# SAM9X60D1G_SOM register map
Vendor: Microchip Technology; Series: SAM9X6; File version: 0
Registers are 32-bit, read-write, reset 0x0 unless marked. A register's access mark holds for its fields unless they carry their own. Offsets are from the block's base; [hi:lo] are bit positions; lines under a group give offsets from that group; {n}, {i} and the like mark numbered series; 'fields as' and 'values as' point back to an identical list.

## PIT — Periodic Interval Timer
Base 0xFFFFFE40
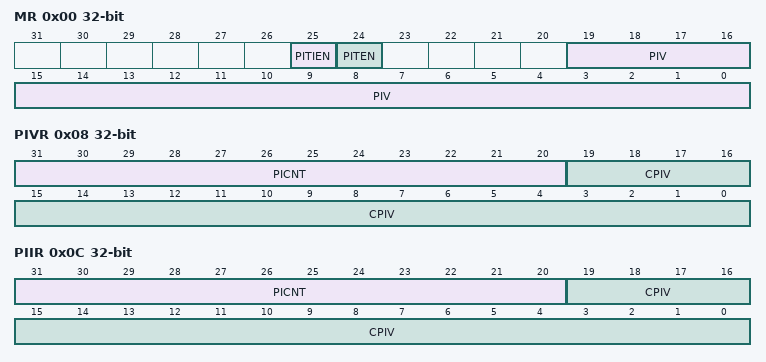
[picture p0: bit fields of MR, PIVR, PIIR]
0x00 MR — Mode Register
  [25] PITIEN — Periodic Interval Timer Interrupt Enable
  [24] PITEN — Period Interval Timer Enabled
  [19:0] PIV — Periodic Interval Value
0x04 SR ro — Status Register
  [0] PITS — Periodic Interval Timer Status
0x08 PIVR ro — Periodic Interval Value Register
  [31:20] PICNT — Periodic Interval Counter
  [19:0] CPIV — Current Periodic Interval Value
0x0C PIIR ro — Periodic Interval Image Register
  fields as PIVR

## PIT64B — Periodic Interval Timer 64-bit
Base 0xF0028000
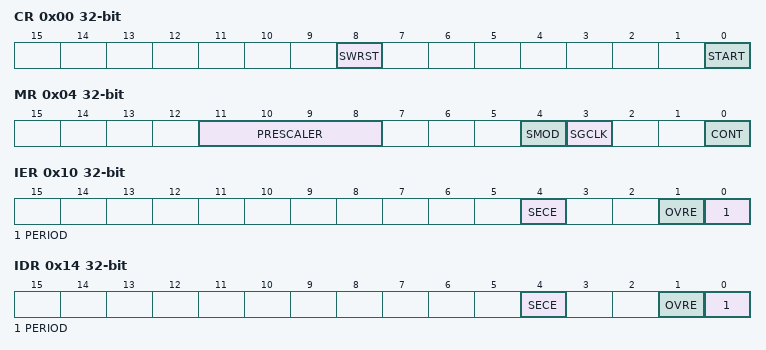
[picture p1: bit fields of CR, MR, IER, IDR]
0x00 CR wo — Control Register
  [8] SWRST — Software Reset
  [0] START — Start Timer
0x04 MR — Mode Register
  [11:8] PRESCALER — Prescaler Period
  [4] SMOD — Start Mode
  [3] SGCLK — Generic Clock Selection Enable
  [0] CONT — Continuous Mode
0x08 LSBPR — LSB Period Register
  [31:0] LSBPERIOD — 32 LSB of the Timer Period
0x0C MSBPR — MSB Period Register
  [31:0] MSBPERIOD — 32 MSB of the Timer Period
0x10 IER wo — Interrupt Enable Register
  [4] SECE — Safety and/or Security Report Interrupt Enable
  [1] OVRE — Overrun Error Interrupt Enable
  [0] PERIOD — Elapsed Timer Period Interrupt Enable
0x14 IDR wo — Interrupt Disable Register
  [4] SECE — Safety and/or Security Report Interrupt Disable
  [1] OVRE — Overrun Error Interrupt Disable
  [0] PERIOD — Elapsed Timer Period Interrupt Disable
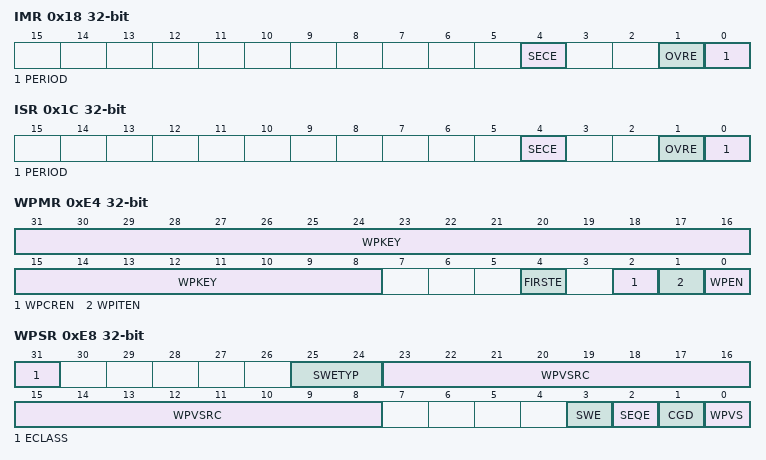
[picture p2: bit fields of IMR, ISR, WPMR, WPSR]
0x18 IMR ro — Interrupt Mask Register
  [4] SECE — Safety and/or Security Report Interrupt Mask
  [1] OVRE — Overrun Error Interrupt Mask
  [0] PERIOD — Elapsed Timer Period Interrupt Mask
0x1C ISR ro — Interrupt Status Register
  [4] SECE — Safety/Security Report (cleared on read)
  [1] OVRE — Overrun Error (cleared on read)
  [0] PERIOD — Elapsed Timer Period Status Flag (cleared on read)
0x20 TLSBR ro — Timer LSB Current Value Register
  [31:0] LSBTIMER — Current 32 LSB of the Timer
0x24 TMSBR ro — Timer MSB Current Value Register
  [31:0] MSBTIMER — Current 32 MSB of the Timer
0xE4 WPMR — Write Protection Mode Register
  [31:8] WPKEY — Write Protection Key
    0x504954=PASSWD (Writing any other value in this field aborts the write operation of the WPCREN, WPITEN and WPEN bits. Always reads as 0.)
  [4] FIRSTE — First Error Report Enable
  [2] WPCREN — Write Protection Control Enable
  [1] WPITEN — Write Protection Interruption Enable
  [0] WPEN — Write Protection Enable
0xE8 WPSR ro — Write Protection Status Register
  [31] ECLASS — Software Error Class (cleared on read)
    0=WARNING (An abnormal access that does not affect system functionality.); 1=ERROR (A write access is performed into PIT64B_MR, PIT64B_LSBR, PIT64B_MSBR while the PIT64B is running.)
  [25:24] SWETYP — Software Error Type (cleared on read)
    0=READ_WO (A write-only register has been read (warning).); 1=WRITE_RO (A write access has been performed on a read-only register (Warning).); 2=UNDEF_RW (Access to an undefined address (warning).); 3=WEIRD_ACTION (A write access is performed into PIT64B_MR, PIT64B_LSBR, PIT64B_MSBR while the PIT64B is running (abnormal).)
  [23:8] WPVSRC — Write Protection Violation Source
  [3] SWE — Software Control Error (cleared on read)
  [2] SEQE — Internal Sequencer Error (cleared on read)
  [1] CGD — Clock Glitch Detected (cleared on read)
  [0] WPVS — Write Protection Violation Status (cleared on read)

## PMECC — Programmable Multibit Error Correction Code Controller
Base 0xFFFFE000
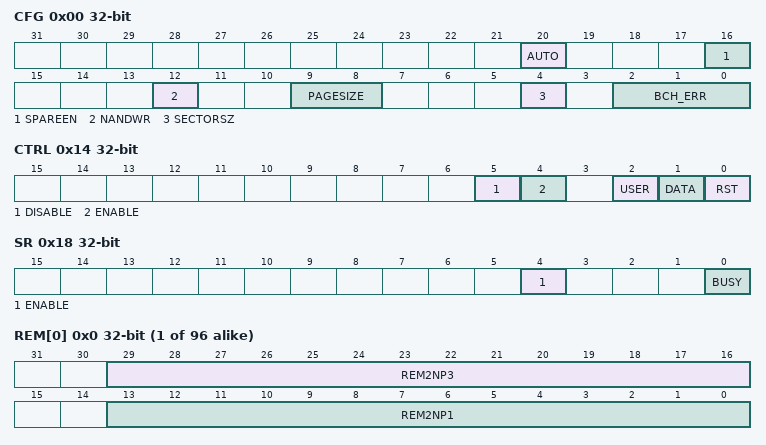
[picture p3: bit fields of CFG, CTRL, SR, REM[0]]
0x00 CFG — PMECC Configuration Register
  [20] AUTO — Automatic Mode Enable
  [16] SPAREEN — Spare Enable
  [12] NANDWR — NAND Write Access
  [9:8] PAGESIZE — Number of Sectors in the Page
    0=PAGESIZE_1SEC (1 sector for main area (512 or 1024 bytes)); 1=PAGESIZE_2SEC (2 sectors for main area (1024 or 2048 bytes)); 2=PAGESIZE_4SEC (4 sectors for main area (2048 or 4096 bytes)); 3=PAGESIZE_8SEC (8 sectors for main area (4096 or 8192 bytes))
  [4] SECTORSZ — Sector Size
  [2:0] BCH_ERR — Error Correct Capability
    0=2 errors; 1=4 errors; 2=8 errors; 3=12 errors; 4=24 errors
0x04 SAREA — PMECC Spare Area Size Register
  [8:0] SPARESIZE — Spare Area Size
0x08 SADDR — PMECC Start Address Register
  [8:0] STARTADDR — ECC Area Start Address (byte oriented address)
0x0C EADDR — PMECC End Address Register
  [8:0] ENDADDR — ECC Area End Address (byte oriented address)
0x10 CLK — PMECC Clock Control Register
  [2:0] CLKCTRL — Clock Control Register
0x14 CTRL wo — PMECC Control Register
  [5] DISABLE — PMECC Module Disable
  [4] ENABLE — PMECC Module Enable
  [2] USER — Start a User Mode Phase
  [1] DATA — Start a Data Phase
  [0] RST — Reset the PMECC Module
0x18 SR ro — PMECC Status Register
  [4] ENABLE — PMECC Module Status
  [0] BUSY — The Kernel of the PMECC is Busy
0x1C IER wo — PMECC Interrupt Enable register
  [0] ERRIE — Error Interrupt Enable
0x20 IDR wo — PMECC Interrupt Disable Register
  [0] ERRID — Error Interrupt Disable
0x24 IMR ro — PMECC Interrupt Mask Register
  [0] ERRIM — Error Interrupt Mask
0x28 ISR ro — PMECC Interrupt Status Register
  [7:0] ERRIS — Error Interrupt Status
{0x40+0x40*i} PMECC_ECC[{i}] (i=0..7) group
  {0x0+4j} ECC[{j}] (j=0..10) ro — PMECC ECC 0 Register (sec_num = 0)
    [31:0] ECC — BCH Redundancy
{0x240+0x40*i} PMECC_REM[{i}] (i=0..7) group
  {0x0+4j} REM[{j}] (j=0..11) ro — PMECC REM 0 Register (sec_num = 0)
    [29:16] REM2NP3 — BCH Remainder 2 * N + 3
    [13:0] REM2NP1 — BCH Remainder 2 * N + 1
